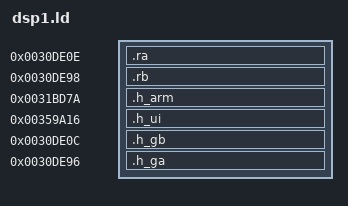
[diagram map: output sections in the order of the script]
SECTIONS
{
  .ra    0x30de0e : { *(.ra) }
  .rb    0x30de98 : { *(.rb) }
  .h_arm 0x31bd7a : { *(.h_arm) }
  .h_ui  0x359a16 : { *(.h_ui) }
  .h_gb  0x30de0c : { *(.h_gb) }
  .h_ga  0x30de96 : { *(.h_ga) }
}
